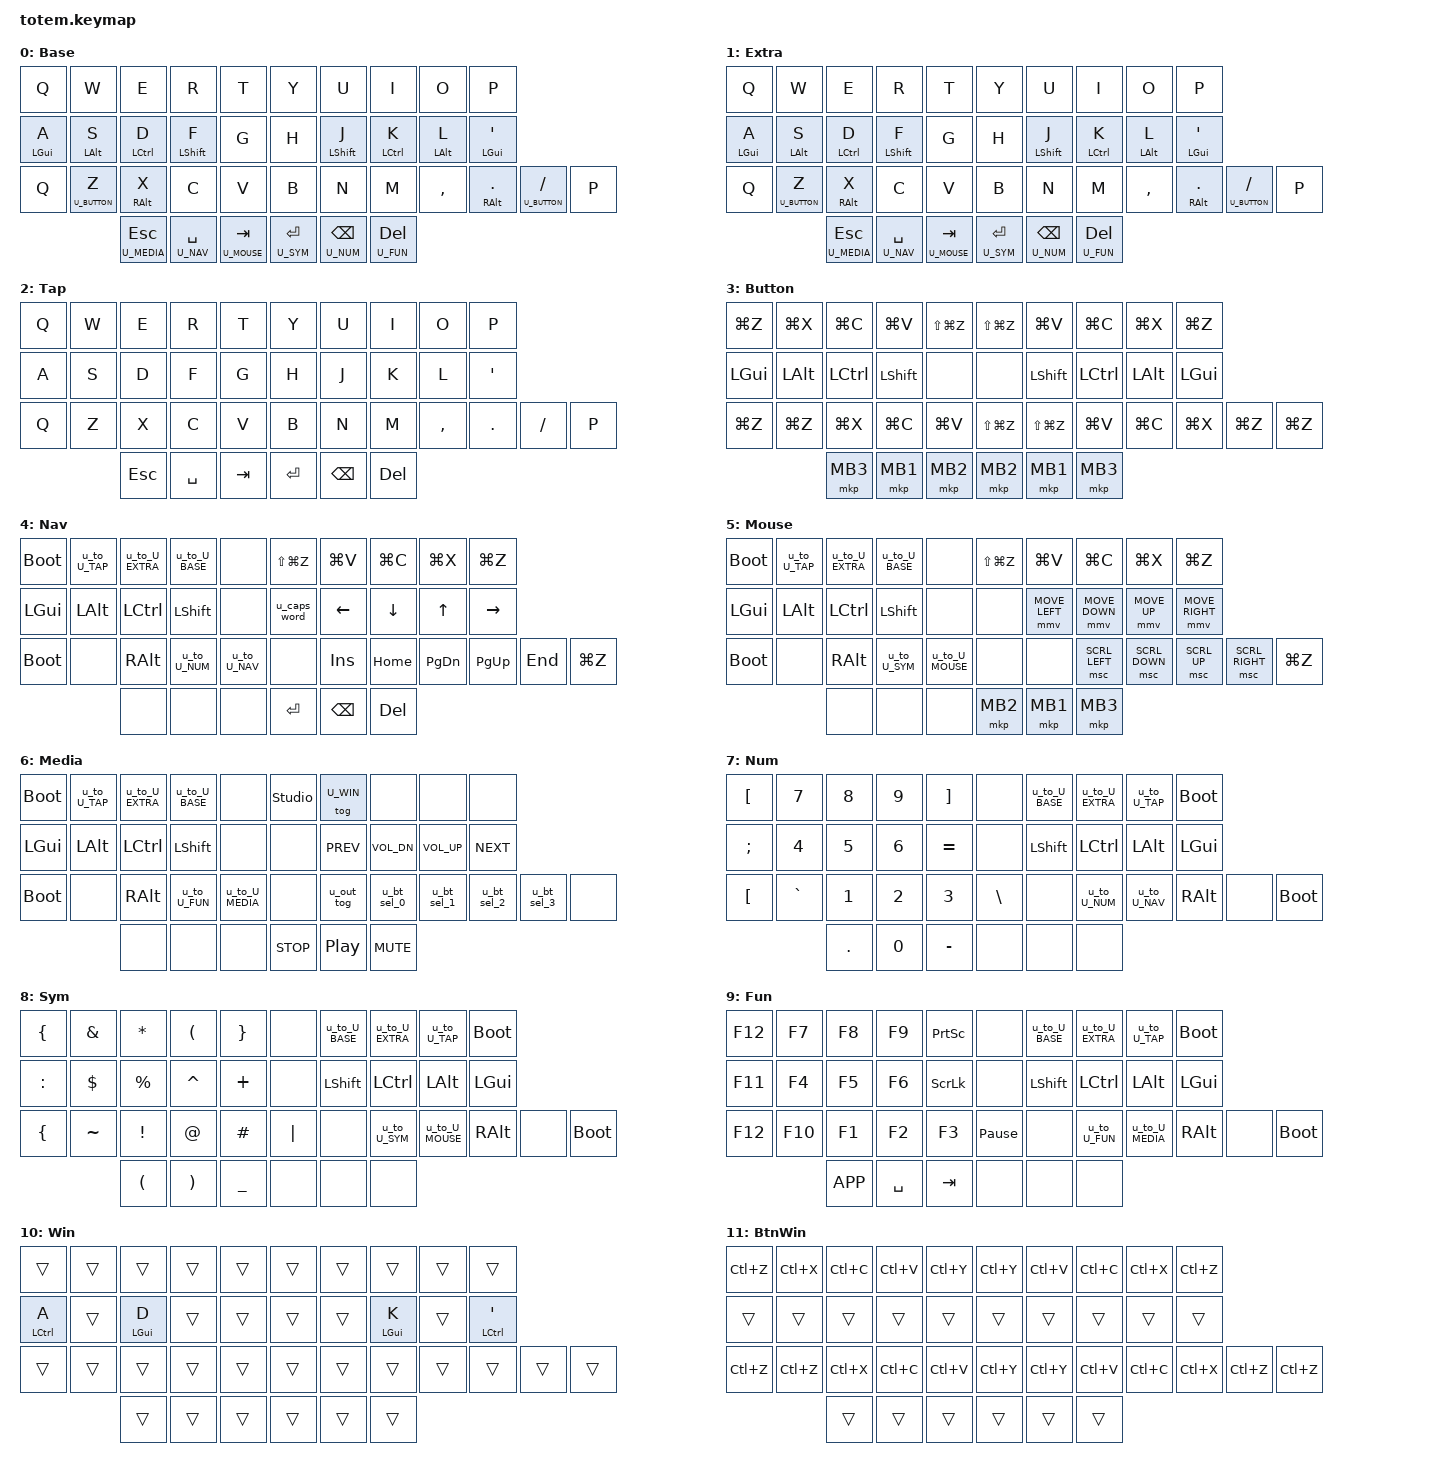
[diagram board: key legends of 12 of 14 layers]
//
// Miryoku layout for the GEIST Totem (38-key), translated from
// https://github.com/manna-harbour/miryoku_zmk for modern ZMK
// (Zephyr 4.1, xiao_ble//zmk).
//
// Cross-platform: defaults to macOS (Cmd-based clipboard, GUI on home-row
// pinky / CTRL on middle finger). Toggle the Win flag layer with
// `&tog U_WIN` (placed on the Media layer) to swap to Windows/Linux mode:
// the Cut/Copy/Paste/Undo/Redo bindings become Ctrl-based and the
// home-row pinky/middle mods swap (CTRL on pinky, GUI on middle), via
// overlay layers triggered by zmk,conditional-layers.
//

#include <behaviors.dtsi>
#include <dt-bindings/zmk/bt.h>
#include <dt-bindings/zmk/keys.h>
#include <dt-bindings/zmk/modifiers.h>
#include <dt-bindings/zmk/outputs.h>
#include <dt-bindings/zmk/pointing.h>

#define U_BASE       0
#define U_EXTRA      1
#define U_TAP        2
#define U_BUTTON     3
#define U_NAV        4
#define U_MOUSE      5
#define U_MEDIA      6
#define U_NUM        7
#define U_SYM        8
#define U_FUN        9
#define U_WIN        10
#define U_BUTTON_WIN 11
#define U_NAV_WIN    12
#define U_MOUSE_WIN  13

#define U_TAPPING_TERM 300

#define U_NP &none
#define U_NA &none
#define U_NU &none

#define U_BTN1 &mkp MB1
#define U_BTN2 &mkp MB2
#define U_BTN3 &mkp MB3
#define U_MS_D &mmv MOVE_DOWN
#define U_MS_L &mmv MOVE_LEFT
#define U_MS_R &mmv MOVE_RIGHT
#define U_MS_U &mmv MOVE_UP
#define U_WH_D &msc SCRL_DOWN
#define U_WH_L &msc SCRL_LEFT
#define U_WH_R &msc SCRL_RIGHT
#define U_WH_U &msc SCRL_UP

// XIAO BLE has no underglow / external power; stub these to no-op.
#define U_RGB_TOG &none
#define U_RGB_EFF &none
#define U_RGB_HUI &none
#define U_RGB_SAI &none
#define U_RGB_BRI &none
#define U_EP_TOG  &none

#define U_BOOT &bootloader

// Default (macOS) clipboard, used by the Button/Nav/Mouse layers.
#define U_RDO &kp LS(LG(Z))
#define U_PST &kp LG(V)
#define U_CPY &kp LG(C)
#define U_CUT &kp LG(X)
#define U_UND &kp LG(Z)

// Windows/Linux clipboard, used by the *_win overlay layers (Ctrl-based).
#define W_RDO &kp LC(Y)
#define W_PST &kp LC(V)
#define W_CPY &kp LC(C)
#define W_CUT &kp LC(X)
#define W_UND &kp LC(Z)

&mmv {
    acceleration-exponent = <1>;
    time-to-max-speed-ms = <1500>;
    delay-ms = <0>;
};

/ {
    behaviors {
        u_mt: u_mt {
            compatible = "zmk,behavior-hold-tap";
            #binding-cells = <2>;
            tapping-term-ms = <U_TAPPING_TERM>;
            flavor = "tap-preferred";
            bindings = <&kp>, <&kp>;
        };
        u_lt: u_lt {
            compatible = "zmk,behavior-hold-tap";
            #binding-cells = <2>;
            tapping-term-ms = <U_TAPPING_TERM>;
            flavor = "tap-preferred";
            bindings = <&mo>, <&kp>;
        };
        u_caps_word: u_caps_word {
            compatible = "zmk,behavior-mod-morph";
            #binding-cells = <0>;
            bindings = <&caps_word>, <&kp CAPS>;
            mods = <(MOD_LSFT|MOD_RSFT)>;
        };
        u_out_tog: u_out_tog {
            compatible = "zmk,behavior-mod-morph";
            #binding-cells = <0>;
            bindings = <&out OUT_TOG>, <&out OUT_USB>;
            mods = <(MOD_LSFT|MOD_RSFT)>;
        };
        u_bt_sel_0: u_bt_sel_0 { compatible = "zmk,behavior-mod-morph"; #binding-cells = <0>; bindings = <&bt BT_SEL 0>, <&u_macro_bt_clr_0>; mods = <(MOD_LSFT|MOD_RSFT)>; };
        u_bt_sel_1: u_bt_sel_1 { compatible = "zmk,behavior-mod-morph"; #binding-cells = <0>; bindings = <&bt BT_SEL 1>, <&u_macro_bt_clr_1>; mods = <(MOD_LSFT|MOD_RSFT)>; };
        u_bt_sel_2: u_bt_sel_2 { compatible = "zmk,behavior-mod-morph"; #binding-cells = <0>; bindings = <&bt BT_SEL 2>, <&u_macro_bt_clr_2>; mods = <(MOD_LSFT|MOD_RSFT)>; };
        u_bt_sel_3: u_bt_sel_3 { compatible = "zmk,behavior-mod-morph"; #binding-cells = <0>; bindings = <&bt BT_SEL 3>, <&u_macro_bt_clr_3>; mods = <(MOD_LSFT|MOD_RSFT)>; };
        u_to_U_BASE:  u_to_U_BASE  { compatible = "zmk,behavior-tap-dance"; #binding-cells = <0>; tapping-term-ms = <U_TAPPING_TERM>; bindings = <&none>, <&to U_BASE>; };
        u_to_U_EXTRA: u_to_U_EXTRA { compatible = "zmk,behavior-tap-dance"; #binding-cells = <0>; tapping-term-ms = <U_TAPPING_TERM>; bindings = <&none>, <&to U_EXTRA>; };
        u_to_U_TAP:   u_to_U_TAP   { compatible = "zmk,behavior-tap-dance"; #binding-cells = <0>; tapping-term-ms = <U_TAPPING_TERM>; bindings = <&none>, <&to U_TAP>; };
        u_to_U_NAV:   u_to_U_NAV   { compatible = "zmk,behavior-tap-dance"; #binding-cells = <0>; tapping-term-ms = <U_TAPPING_TERM>; bindings = <&none>, <&to U_NAV>; };
        u_to_U_MOUSE: u_to_U_MOUSE { compatible = "zmk,behavior-tap-dance"; #binding-cells = <0>; tapping-term-ms = <U_TAPPING_TERM>; bindings = <&none>, <&to U_MOUSE>; };
        u_to_U_MEDIA: u_to_U_MEDIA { compatible = "zmk,behavior-tap-dance"; #binding-cells = <0>; tapping-term-ms = <U_TAPPING_TERM>; bindings = <&none>, <&to U_MEDIA>; };
        u_to_U_NUM:   u_to_U_NUM   { compatible = "zmk,behavior-tap-dance"; #binding-cells = <0>; tapping-term-ms = <U_TAPPING_TERM>; bindings = <&none>, <&to U_NUM>; };
        u_to_U_SYM:   u_to_U_SYM   { compatible = "zmk,behavior-tap-dance"; #binding-cells = <0>; tapping-term-ms = <U_TAPPING_TERM>; bindings = <&none>, <&to U_SYM>; };
        u_to_U_FUN:   u_to_U_FUN   { compatible = "zmk,behavior-tap-dance"; #binding-cells = <0>; tapping-term-ms = <U_TAPPING_TERM>; bindings = <&none>, <&to U_FUN>; };
    };

    macros {
        u_macro_bt_clr_0: u_macro_bt_clr_0 { compatible = "zmk,behavior-macro"; #binding-cells = <0>; wait-ms = <0>; bindings = <&bt BT_SEL 0 &bt BT_CLR>; };
        u_macro_bt_clr_1: u_macro_bt_clr_1 { compatible = "zmk,behavior-macro"; #binding-cells = <0>; wait-ms = <0>; bindings = <&bt BT_SEL 1 &bt BT_CLR>; };
        u_macro_bt_clr_2: u_macro_bt_clr_2 { compatible = "zmk,behavior-macro"; #binding-cells = <0>; wait-ms = <0>; bindings = <&bt BT_SEL 2 &bt BT_CLR>; };
        u_macro_bt_clr_3: u_macro_bt_clr_3 { compatible = "zmk,behavior-macro"; #binding-cells = <0>; wait-ms = <0>; bindings = <&bt BT_SEL 3 &bt BT_CLR>; };
    };

    conditional_layers {
        compatible = "zmk,conditional-layers";
        button_win { if-layers = <U_WIN U_BUTTON>; then-layer = <U_BUTTON_WIN>; };
        nav_win    { if-layers = <U_WIN U_NAV>;    then-layer = <U_NAV_WIN>; };
        mouse_win  { if-layers = <U_WIN U_MOUSE>;  then-layer = <U_MOUSE_WIN>; };
    };

    keymap {
        compatible = "zmk,keymap";

        // Totem 38-key physical order per row (Miryoku totem mapping):
        //   row 1:               K00 K01 K02 K03 K04   K05 K06 K07 K08 K09
        //   row 2:               K10 K11 K12 K13 K14   K15 K16 K17 K18 K19
        //   row 3 (12): K00*     K20 K21 K22 K23 K24   K25 K26 K27 K28 K29   K09*
        //   thumbs (6):              K32 K33 K34   K35 K36 K37
        // K00*/K09* are duplicates of the top-row outer corners.

        base {
            display-name = "Base";
            bindings = <
&kp Q                &kp W              &kp E              &kp R              &kp T                &kp Y                &kp U              &kp I              &kp O              &kp P
&u_mt LGUI A         &u_mt LALT S       &u_mt LCTRL D      &u_mt LSHFT F      &kp G                &kp H                &u_mt LSHFT J      &u_mt LCTRL K      &u_mt LALT L       &u_mt LGUI SQT
&kp Q                &u_lt U_BUTTON Z   &u_mt RALT X       &kp C              &kp V                &kp B                &kp N              &kp M              &kp COMMA          &u_mt RALT DOT     &u_lt U_BUTTON SLASH   &kp P
                                        &u_lt U_MEDIA ESC  &u_lt U_NAV SPACE  &u_lt U_MOUSE TAB    &u_lt U_SYM RET      &u_lt U_NUM BSPC   &u_lt U_FUN DEL
            >;
        };

        extra {
            display-name = "Extra";
            bindings = <
&kp Q                &kp W              &kp E              &kp R              &kp T                &kp Y                &kp U              &kp I              &kp O              &kp P
&u_mt LGUI A         &u_mt LALT S       &u_mt LCTRL D      &u_mt LSHFT F      &kp G                &kp H                &u_mt LSHFT J      &u_mt LCTRL K      &u_mt LALT L       &u_mt LGUI SQT
&kp Q                &u_lt U_BUTTON Z   &u_mt RALT X       &kp C              &kp V                &kp B                &kp N              &kp M              &kp COMMA          &u_mt RALT DOT     &u_lt U_BUTTON SLASH   &kp P
                                        &u_lt U_MEDIA ESC  &u_lt U_NAV SPACE  &u_lt U_MOUSE TAB    &u_lt U_SYM RET      &u_lt U_NUM BSPC   &u_lt U_FUN DEL
            >;
        };

        tap {
            display-name = "Tap";
            bindings = <
&kp Q                &kp W              &kp E              &kp R              &kp T                &kp Y                &kp U              &kp I              &kp O              &kp P
&kp A                &kp S              &kp D              &kp F              &kp G                &kp H                &kp J              &kp K              &kp L              &kp SQT
&kp Q                &kp Z              &kp X              &kp C              &kp V                &kp B                &kp N              &kp M              &kp COMMA          &kp DOT            &kp SLASH              &kp P
                                        &kp ESC            &kp SPACE          &kp TAB              &kp RET              &kp BSPC           &kp DEL
            >;
        };

        button {
            display-name = "Button";
            bindings = <
U_UND                U_CUT              U_CPY              U_PST              U_RDO                U_RDO                U_PST              U_CPY              U_CUT              U_UND
&kp LGUI             &kp LALT           &kp LCTRL          &kp LSHFT          U_NU                 U_NU                 &kp LSHFT          &kp LCTRL          &kp LALT           &kp LGUI
U_UND                U_UND              U_CUT              U_CPY              U_PST                U_RDO                U_RDO              U_PST              U_CPY              U_CUT              U_UND                  U_UND
                                        U_BTN3             U_BTN1             U_BTN2               U_BTN2               U_BTN1             U_BTN3
            >;
        };

        nav {
            display-name = "Nav";
            bindings = <
U_BOOT               &u_to_U_TAP        &u_to_U_EXTRA      &u_to_U_BASE       U_NA                 U_RDO                U_PST              U_CPY              U_CUT              U_UND
&kp LGUI             &kp LALT           &kp LCTRL          &kp LSHFT          U_NA                 &u_caps_word         &kp LEFT           &kp DOWN           &kp UP             &kp RIGHT
U_BOOT               U_NA               &kp RALT           &u_to_U_NUM        &u_to_U_NAV          U_NA                 &kp INS            &kp HOME           &kp PG_DN          &kp PG_UP          &kp END                U_UND
                                        U_NA               U_NA               U_NA                 &kp RET              &kp BSPC           &kp DEL
            >;
        };

        mouse {
            display-name = "Mouse";
            bindings = <
U_BOOT               &u_to_U_TAP        &u_to_U_EXTRA      &u_to_U_BASE       U_NA                 U_RDO                U_PST              U_CPY              U_CUT              U_UND
&kp LGUI             &kp LALT           &kp LCTRL          &kp LSHFT          U_NA                 U_NU                 U_MS_L             U_MS_D             U_MS_U             U_MS_R
U_BOOT               U_NA               &kp RALT           &u_to_U_SYM        &u_to_U_MOUSE        U_NA                 U_NU               U_WH_L             U_WH_D             U_WH_U             U_WH_R                 U_UND
                                        U_NA               U_NA               U_NA                 U_BTN2               U_BTN1             U_BTN3
            >;
        };

        media {
            display-name = "Media";
            bindings = <
U_BOOT               &u_to_U_TAP        &u_to_U_EXTRA      &u_to_U_BASE       U_NA                 &studio_unlock       &tog U_WIN         U_RGB_HUI          U_RGB_SAI          U_RGB_BRI
&kp LGUI             &kp LALT           &kp LCTRL          &kp LSHFT          U_NA                 U_EP_TOG             &kp C_PREV         &kp C_VOL_DN       &kp C_VOL_UP       &kp C_NEXT
U_BOOT               U_NA               &kp RALT           &u_to_U_FUN        &u_to_U_MEDIA        U_NA                 &u_out_tog         &u_bt_sel_0        &u_bt_sel_1        &u_bt_sel_2        &u_bt_sel_3            U_RGB_BRI
                                        U_NA               U_NA               U_NA                 &kp C_STOP           &kp C_PP           &kp C_MUTE
            >;
        };

        num {
            display-name = "Num";
            bindings = <
&kp LBKT             &kp N7             &kp N8             &kp N9             &kp RBKT             U_NA                 &u_to_U_BASE       &u_to_U_EXTRA      &u_to_U_TAP        U_BOOT
&kp SEMI             &kp N4             &kp N5             &kp N6             &kp EQUAL            U_NA                 &kp LSHFT          &kp LCTRL          &kp LALT           &kp LGUI
&kp LBKT             &kp GRAVE          &kp N1             &kp N2             &kp N3               &kp BSLH             U_NA               &u_to_U_NUM        &u_to_U_NAV        &kp RALT           U_NA                   U_BOOT
                                        &kp DOT            &kp N0             &kp MINUS            U_NA                 U_NA               U_NA
            >;
        };

        sym {
            display-name = "Sym";
            bindings = <
&kp LBRC             &kp AMPS           &kp ASTRK          &kp LPAR           &kp RBRC             U_NA                 &u_to_U_BASE       &u_to_U_EXTRA      &u_to_U_TAP        U_BOOT
&kp COLON            &kp DLLR           &kp PRCNT          &kp CARET          &kp PLUS             U_NA                 &kp LSHFT          &kp LCTRL          &kp LALT           &kp LGUI
&kp LBRC             &kp TILDE          &kp EXCL           &kp AT             &kp HASH             &kp PIPE             U_NA               &u_to_U_SYM        &u_to_U_MOUSE      &kp RALT           U_NA                   U_BOOT
                                        &kp LPAR           &kp RPAR           &kp UNDER            U_NA                 U_NA               U_NA
            >;
        };

        fun {
            display-name = "Fun";
            bindings = <
&kp F12              &kp F7             &kp F8             &kp F9             &kp PSCRN            U_NA                 &u_to_U_BASE       &u_to_U_EXTRA      &u_to_U_TAP        U_BOOT
&kp F11              &kp F4             &kp F5             &kp F6             &kp SLCK             U_NA                 &kp LSHFT          &kp LCTRL          &kp LALT           &kp LGUI
&kp F12              &kp F10            &kp F1             &kp F2             &kp F3               &kp PAUSE_BREAK      U_NA               &u_to_U_FUN        &u_to_U_MEDIA      &kp RALT           U_NA                   U_BOOT
                                        &kp K_APP          &kp SPACE          &kp TAB              U_NA                 U_NA               U_NA
            >;
        };

        // Sticky flag layer toggled with `&tog U_WIN` from the Media layer.
        // Overrides the home-row pinky/middle mods to swap GUI<->CTRL for
        // Windows orientation (CTRL on pinky, GUI on middle); activates
        // the *_win overlays via zmk,conditional-layers when combined with
        // Button/Nav/Mouse.
        win {
            display-name = "Win";
            bindings = <
&trans               &trans             &trans             &trans             &trans               &trans               &trans             &trans             &trans             &trans
&u_mt LCTRL A        &trans             &u_mt LGUI D       &trans             &trans               &trans               &trans             &u_mt LGUI K       &trans             &u_mt LCTRL SQT
&trans               &trans             &trans             &trans             &trans               &trans               &trans             &trans             &trans             &trans             &trans                 &trans
                                        &trans             &trans             &trans               &trans               &trans             &trans
            >;
        };

        button_win {
            display-name = "BtnWin";
            bindings = <
W_UND                W_CUT              W_CPY              W_PST              W_RDO                W_RDO                W_PST              W_CPY              W_CUT              W_UND
&trans               &trans             &trans             &trans             &trans               &trans               &trans             &trans             &trans             &trans
W_UND                W_UND              W_CUT              W_CPY              W_PST                W_RDO                W_RDO              W_PST              W_CPY              W_CUT              W_UND                  W_UND
                                        &trans             &trans             &trans               &trans               &trans             &trans
            >;
        };

        nav_win {
            display-name = "NavWin";
            bindings = <
&trans               &trans             &trans             &trans             &trans               W_RDO                W_PST              W_CPY              W_CUT              W_UND
&trans               &trans             &trans             &trans             &trans               &trans               &trans             &trans             &trans             &trans
&trans               &trans             &trans             &trans             &trans               &trans               &trans             &trans             &trans             &trans             &trans                 W_UND
                                        &trans             &trans             &trans               &trans               &trans             &trans
            >;
        };

        mouse_win {
            display-name = "MseWin";
            bindings = <
&trans               &trans             &trans             &trans             &trans               W_RDO                W_PST              W_CPY              W_CUT              W_UND
&trans               &trans             &trans             &trans             &trans               &trans               &trans             &trans             &trans             &trans
&trans               &trans             &trans             &trans             &trans               &trans               &trans             &trans             &trans             &trans             &trans                 W_UND
                                        &trans             &trans             &trans               &trans               &trans             &trans
            >;
        };

    };
};
